# RP2040 register map
Vendor: Raspberry Pi; File version: 0.1
CPU: CM0PLUS r0p1, little endian, MPU, no FPU, VTOR, 2 interrupt priority bits, 26 interrupts
Registers are 32-bit, read-write, reset 0x0 unless marked. A register's access mark holds for its fields unless they carry their own. Offsets are from the block's base; [hi:lo] are bit positions; {n}, {i} and the like mark numbered series; 'fields as' and 'values as' point back to an identical list.

## WATCHDOG
Base 0x40058000
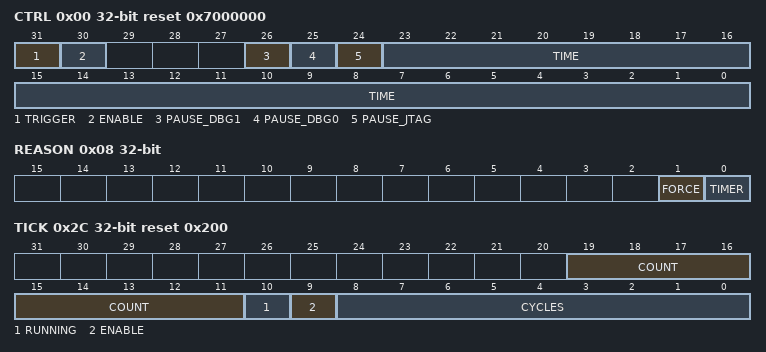
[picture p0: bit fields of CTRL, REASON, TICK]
0x00 CTRL access per field reset 0x7000000 — Watchdog control. The rst_wdsel register determines which subsystems are reset when the watchdog is triggered. The watchdog can be triggered in software.
  [31] TRIGGER rw write-clears — Trigger a watchdog reset
  [30] ENABLE rw — When not enabled the watchdog timer is paused
  [26] PAUSE_DBG1 rw — Pause the watchdog timer when processor 1 is in debug mode
  [25] PAUSE_DBG0 rw — Pause the watchdog timer when processor 0 is in debug mode
  [24] PAUSE_JTAG rw — Pause the watchdog timer when JTAG is accessing the bus fabric
  [23:0] TIME ro — Indicates the number of ticks / 2 (see errata RP2040-E1) before a watchdog reset will be triggered
0x04 LOAD wo — Load the watchdog timer. The maximum setting is 0xffffff which corresponds to 0xffffff / 2 ticks before triggering a watchdog reset (see errata RP2040-E1).
  [23:0] LOAD
0x08 REASON ro — Logs the reason for the last reset. Both bits are zero for the case of a hardware reset.
  [1] FORCE, [0] TIMER
{0xC+4i} SCRATCH{i} (i=0..7) — Scratch register. Information persists through soft reset of the chip.
0x2C TICK access per field reset 0x200 — Controls the tick generator
  [19:11] COUNT ro — Count down timer: the remaining number clk_tick cycles before the next tick is generated.
  [10] RUNNING ro — Is the tick generator running?
  [9] ENABLE rw — start / stop tick generation
  [8:0] CYCLES rw — Total number of clk_tick cycles before the next tick.

## RTC — Register block to control RTC
Base 0x4005C000
0x00 CLKDIV_M1 — Divider minus 1 for the 1 second counter. Safe to change the value when RTC is not enabled.
  [15:0] CLKDIV_M1
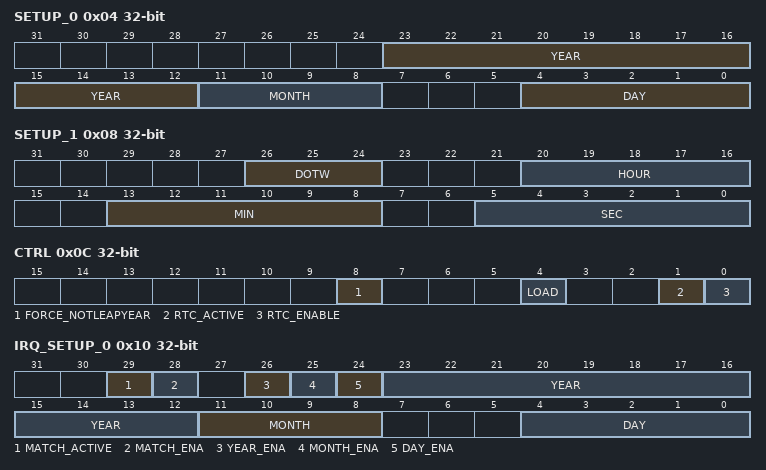
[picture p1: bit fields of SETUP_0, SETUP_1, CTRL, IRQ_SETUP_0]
0x04 SETUP_0 — RTC setup register 0
  [23:12] YEAR
  [11:8] MONTH — Month (1..12)
  [4:0] DAY — Day of the month (1..31)
0x08 SETUP_1 — RTC setup register 1
  [26:24] DOTW — Day of the week: 1-Monday...0-Sunday ISO 8601 mod 7
  [20:16] HOUR — Hours
  [13:8] MIN — Minutes
  [5:0] SEC — Seconds
0x0C CTRL access per field — RTC Control and status
  [8] FORCE_NOTLEAPYEAR rw — If set, leapyear is forced off. Useful for years divisible by 100 but not by 400
  [4] LOAD rw write-clears — Load RTC
  [1] RTC_ACTIVE ro — RTC enabled (running)
  [0] RTC_ENABLE rw — Enable RTC
0x10 IRQ_SETUP_0 access per field — Interrupt setup register 0
  [29] MATCH_ACTIVE ro
  [28] MATCH_ENA rw — Global match enable. Don't change any other value while this one is enabled
  [26] YEAR_ENA rw — Enable year matching
  [25] MONTH_ENA rw — Enable month matching
  [24] DAY_ENA rw — Enable day matching
  [23:12] YEAR rw
  [11:8] MONTH rw — Month (1..12)
  [4:0] DAY rw — Day of the month (1..31)
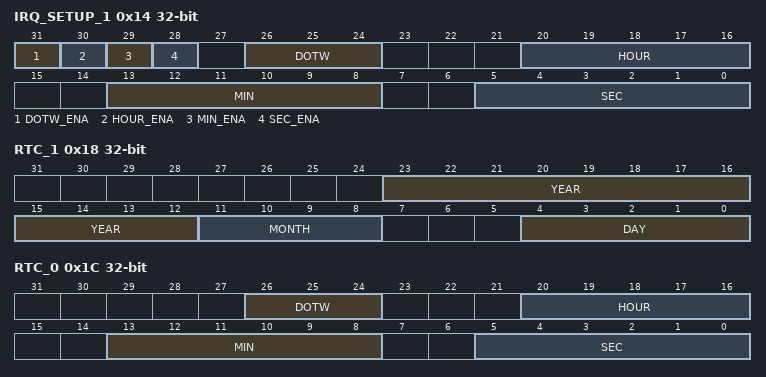
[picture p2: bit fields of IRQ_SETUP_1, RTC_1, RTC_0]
0x14 IRQ_SETUP_1 — Interrupt setup register 1
  [31] DOTW_ENA — Enable day of the week matching
  [30] HOUR_ENA — Enable hour matching
  [29] MIN_ENA — Enable minute matching
  [28] SEC_ENA — Enable second matching
  [26:24] DOTW — Day of the week
  [20:16] HOUR — Hours
  [13:8] MIN — Minutes
  [5:0] SEC — Seconds
0x18 RTC_1 ro — RTC register 1.
  fields as SETUP_0
0x1C RTC_0 ro — RTC register 0. Read this before RTC 1!
  [26:24] DOTW — Day of the week
  [20:16] HOUR — Hours
  [13:8] MIN — Minutes
  [5:0] SEC — Seconds
0x20 INTR ro — Raw Interrupts
  [0] RTC
0x24 INTE — Interrupt Enable
  [0] RTC
0x28 INTF — Interrupt Force
  [0] RTC
0x2C INTS ro — Interrupt status after masking & forcing
  [0] RTC

## ROSC
Base 0x40060000
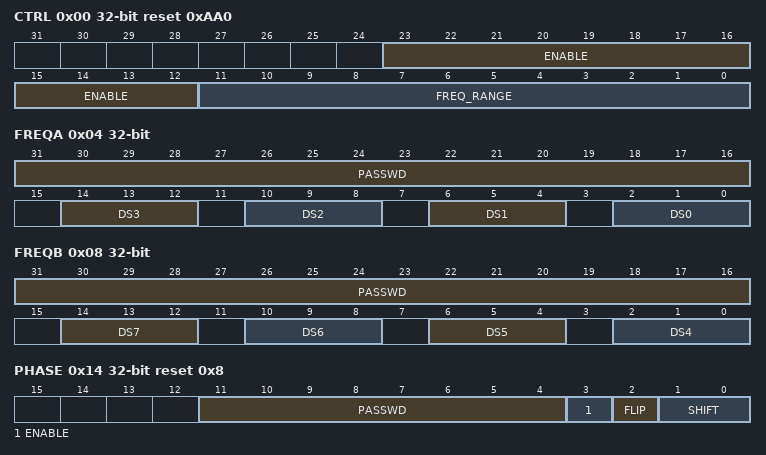
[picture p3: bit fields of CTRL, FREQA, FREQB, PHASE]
0x00 CTRL reset 0xAA0 — Ring Oscillator control
  [23:12] ENABLE — On power-up this field is initialised to ENABLE. The system clock must be switched to another source before setting this field to DISABLE otherwise the chip will lock up. The 12-bit code is intended to give some protection against accidental writes. An invalid setting will enable the oscillator.
    0xD1E=DISABLE; 0xFAB=ENABLE
  [11:0] FREQ_RANGE — Controls the number of delay stages in the ROSC ring. LOW uses stages 0 to 7. MEDIUM uses stages 0 to 5. HIGH uses stages 0 to 3. TOOHIGH uses stages 0 to 1 and should not be used because its frequency exceeds design specifications. The clock output will not glitch when changing the range up one step at a time. The clock output will glitch when changing the range down. Note: the values here are gray coded which is why HIGH comes before TOOHIGH
    0xFA4=LOW; 0xFA5=MEDIUM; 0xFA7=HIGH; 0xFA6=TOOHIGH
0x04 FREQA — The FREQA & FREQB registers control the frequency by controlling the drive strength of each stage. The drive strength has 4 levels determined by the number of bits set. Increasing the number of bits set increases the drive strength and increases the oscillation frequency. 0 bits set is the default drive strength. 1 bit set doubles the drive strength. 2 bits set triples drive strength. 3 bits set quadruples drive strength
  [31:16] PASSWD — Set to 0x9696 to apply the settings. Any other value in this field will set all drive strengths to 0
    0x9696=PASS
  [4n+2:4n] DS{n} (n=0..3) — Stage {n} drive strength
0x08 FREQB — For a detailed description see freqa register
  [31:16] PASSWD — Set to 0x9696 to apply the settings. Any other value in this field will set all drive strengths to 0
    0x9696=PASS
  [4n-14:4n-16] DS{n} (n=4..7) — Stage {n} drive strength
0x0C DORMANT — Ring Oscillator pause control. This is used to save power by pausing the ROSC. On power-up this field is initialised to WAKE. An invalid write will also select WAKE. Warning: setup the irq before selecting dormant mode
0x10 DIV — Controls the output divider
  [11:0] DIV — set to 0xaa0 + div where div = 0 divides by 32 div = 1-31 divides by div any other value sets div=31 this register resets to div=16
    0xAA0=PASS
0x14 PHASE reset 0x8 — Controls the phase shifted output
  [11:4] PASSWD — set to 0xaa any other value enables the output with shift=0
  [3] ENABLE — enable the phase-shifted output this can be changed on-the-fly
  [2] FLIP — invert the phase-shifted output this is ignored when div=1
  [1:0] SHIFT — phase shift the phase-shifted output by SHIFT input clocks this can be changed on-the-fly must be set to 0 before setting div=1
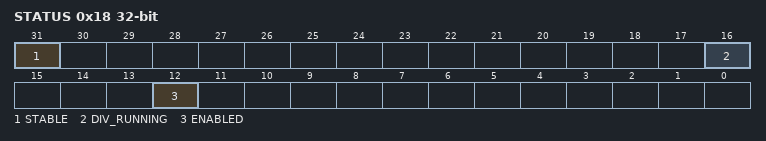
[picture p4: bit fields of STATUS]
0x18 STATUS ro — Ring Oscillator Status
  [31] STABLE — Oscillator is running and stable
  [16] DIV_RUNNING — post-divider is running this resets to 0 but transitions to 1 during chip startup
  [12] ENABLED — Oscillator is enabled but not necessarily running and stable this resets to 0 but transitions to 1 during chip startup
0x1C RANDOMBIT ro reset 0x1 — This just reads the state of the oscillator output so randomness is compromised if the ring oscillator is stopped or run at a harmonic of the bus frequency
  [0] RANDOMBIT

## VREG_AND_CHIP_RESET — control and status for on-chip voltage regulator and chip level reset subsystem
Base 0x40064000
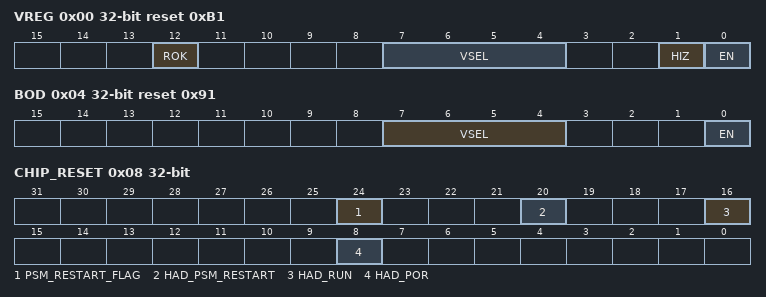
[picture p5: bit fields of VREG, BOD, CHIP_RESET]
0x00 VREG access per field reset 0xB1 — Voltage regulator control and status
  [12] ROK ro — regulation status. 0=not in regulation, 1=in regulation
  [7:4] VSEL rw — Output voltage select for on-chip voltage regulator.
    5=Voltage0_80 (0.80V); 6=Voltage0_85 (0.85V); 7=Voltage0_90 (0.90V); 8=Voltage0_95 (0.95V); 9=Voltage1_00 (1.00V); 10=Voltage1_05 (1.05V); 11=Voltage1_10 (1.10V (default)); 12=Voltage1_15 (1.15V); 13=Voltage1_20 (1.20V); 14=Voltage1_25 (1.25V); 15=Voltage1_30 (1.30V)
  [1] HIZ rw — high impedance mode select. 0=not in high impedance mode, 1=in high impedance mode
  [0] EN rw — enable. 0=not enabled, 1=enabled
0x04 BOD reset 0x91 — brown-out detection control
  [7:4] VSEL — threshold select. 0000 - 0.473V. 0001 - 0.516V. 0010 - 0.559V. 0011 - 0.602V. 0100 - 0.645V. 0101 - 0.688V. 0110 - 0.731V. 0111 - 0.774V. 1000 - 0.817V. 1001 - 0.860V (default). 1010 - 0.903V. 1011 - 0.946V. 1100 - 0.989V. 1101 - 1.032V. 1110 - 1.075V. 1111 - 1.118V
  [0] EN — enable. 0=not enabled, 1=enabled
0x08 CHIP_RESET access per field — Chip reset control and status
  [24] PSM_RESTART_FLAG rw write-1-clears — This is set by psm_restart from the debugger. Its purpose is to branch bootcode to a safe mode when the debugger has issued a psm_restart in order to recover from a boot lock-up. In the safe mode the debugger can repair the boot code, clear this flag then reboot the processor.
  [20] HAD_PSM_RESTART ro — Last reset was from the debug port
  [16] HAD_RUN ro — Last reset was from the RUN pin
  [8] HAD_POR ro — Last reset was from the power-on reset or brown-out detection blocks

## TBMAN — Testbench manager. Allows the programmer to know what platform their software is running on.
Base 0x4006C000
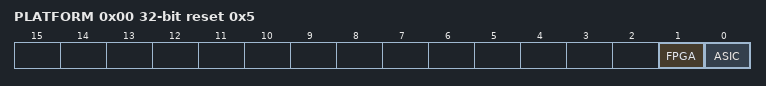
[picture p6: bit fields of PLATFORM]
0x00 PLATFORM ro reset 0x5 — Indicates the type of platform in use
  [1] FPGA — Indicates the platform is an FPGA
  [0] ASIC — Indicates the platform is an ASIC
